# PIC32MZ1064DAG176 device description
Architecture: MIPS; Family: PIC32MZDA; Series: PIC32MZ
Registers are 32-bit, read-write, no defined reset value unless marked. A register's access mark holds for its fields unless they carry their own. Offsets are from the block's base; [hi:lo] are bit positions; {n}, {i} and the like mark numbered series; 'fields as' and 'values as' point back to an identical list.

## SDHC
Instances: SDHC 0x1f8ec004 in periph_indep
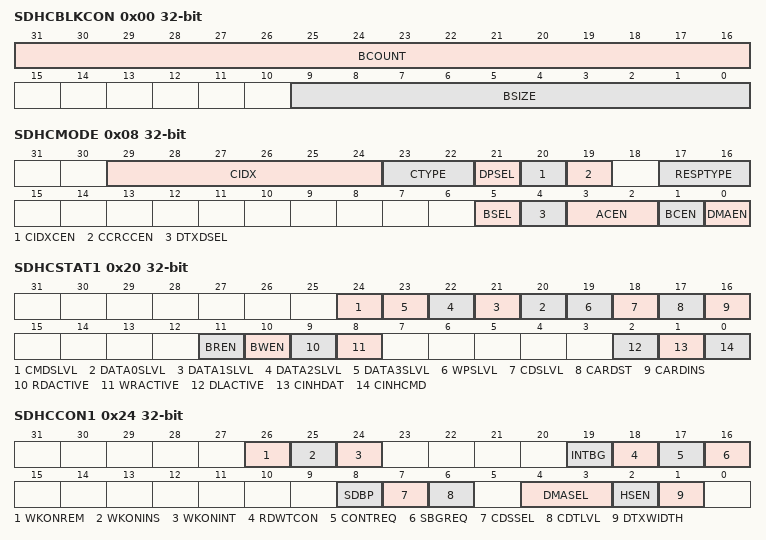
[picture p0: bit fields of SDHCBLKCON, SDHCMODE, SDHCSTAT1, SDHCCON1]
0x00 SDHCBLKCON — SDHC Block Control Register
  [31:16] BCOUNT — Blocks Count for Current Transfer bits
    0=65,535 blocks; 0=2 blocks; 0=1 block; 0=Stop count Blocks Count for Current Transfer bits
  [9:0] BSIZE — Transfer Block Size bits
    0x200=512 bytes; 0x1ff=511 bytes; 2=2 bytes; 1=1 byte; 0=No data transfer
0x04 SDHCARG — SDHC Argument Register
  [31:0] ARG
0x08 SDHCMODE
  [29:24] CIDX
  [23:22] CTYPE — Command Type bits
    3=Abort; 2=Resume; 1=Suspend; 0=Normal
  [21] DPSEL — Data Present Select bit
    1=Data is present; 0=Data is not present
  [20] CIDXCEN — Command Index Check Enable bit
    1=Command index check is enabled; 0=Command index check is disabled
  [19] CCRCCEN — Command CRC Check Enable bit
    1=Command CRC check is enabled; 0=Command CRC check is disabled
  [17:16] RESPTYPE — Response Type Select bits
    3=Response length 48; check busy after response; 2=Response length 48; 1=Response length 136; 0=No response
  [5] BSEL — Multiple/Single Block Select bit
    1=Multiple block, set when issuing multiple transfer commands using DAT lines; 0=Single block
  [4] DTXDSEL — Data Transfer Direction Select bit
    1=Read (card to SDHC); 0=Write (SDHC to card)
  [3:2] ACEN — Auto CMD12 Enable bits
    1=Auto CMD12 is enabled; 0=Auto CMD 12 is disabled
  [1] BCEN — Block Count Enable Bit
    1=Block count is enabled; 0=Block count is disabled
  [0] DMAEN — DMA Enable bit
    1=DMA (ADMA) is used to transfer data; 0=CPU is used to transfer data
{0xC+4i} SDHCRESP{i} ro (i=0..3) — SDHC Response Register
  [31:0] RESP
0x1C SDHCDATA
  [31:0] DATA
0x20 SDHCSTAT1 ro — SDHC Status Register 1
  [24] CMDSLVL — Command Line Signal Level bit
    1=CMD line is high; 0=CMD line is low
  [n+20] DATA{n}SLVL (n=0..3) — DATA{n} Signal Level bit
    1=DAT{n} line is high; 0=DAT{n} line is low
  [19] WPSLVL — Write-protect Signal Level bit
    1=Write-protect is disabled; 0=Write-protect is enabled
  [18] CDSLVL — Card Detect Signal Level bit
    1=Card is present; 0=Card is not present
  [17] CARDST — Card State Stable bit
    1=No card or inserted; 0=Reset or debouncing
  [16] CARDINS — Card Inserted bit
    1=Card inserted; 0=Reset or debouncing or no card
  [11] BREN — Buffer Read Enable bit
    1=Buffer read is enabled; 0=Buffer read is disabled
  [10] BWEN — Buffer Write Enable bit
    1=Buffer write is enabled; 0=Buffer write is disabled
  [9] RDACTIVE — Read Transfer Active bit
    1=Data is being transferred; 0=No valid data
  [8] WRACTIVE — Write Transfer Active bit
    1=Data is being transferred; 0=No valid data
  [2] DLACTIVE — DAT Line Active bit
    1=DAT line is active; 0=DAT line is inactive
  [1] CINHDAT — Command Inhibit bit (DAT) bit
    1=A command that uses the DAT line cannot be issued; 0=A command that uses the DAT line can be issued
  [0] CINHCMD — Command Inhibit bit (CMD) bit
    1=A command cannot be issued; 0=A command can only be issued using the CMD line
0x24 SDHCCON1 — SDHC Control Register 1
  [26] WKONREM — Wake-up Event Enable on SD Card Removal bit
    1=Wake-up event is enabled; 0=Wake-up event is disabled
  [25] WKONINS — Wake-up Event Enable on SD Card Insertion bit
    1=Wake-up event is enabled; 0=Wake-up event is disabled
  [24] WKONINT — Wake-up Event Enable on SD Card Interrupt bit
    1=Wake-up event is enabled; 0=Wake-up event is disabled
  [19] INTBG — Interrupt at Block Gap bit
    1=Interrupt is enabled; 0=Interrupt is disabled
  [18] RDWTCON — Read Wait Control bit
    1=Read wait control is enabled; 0=Read wait control is disabled
  [17] CONTREQ — Continue Request bit
    1=Restart; 0=No effect
  [16] SBGREQ — Stop at Block Gap Request bit
    1=Stop; 0=Transfer
  [8] SDBP — SD Bus Power bit
    1=Bus power is on; 0=Bus power is off
  [7] CDSSEL — Card Detect Signal Selection bit
    1=The card detect test level is select (for test purposes); 0=SDCDx is selected (for normal use)
  [6] CDTLVL — Card Detect Test Level bit
    1=Card is inserted; 0=Card is not inserted
  [4:3] DMASEL — DMA Select bits
    2=32-bit address ADMA2 is selected
  [2] HSEN — High-Speed Enable bit
    1=High-Speed mode is enabled; 0=Normal Speed mode is enabled
  [1] DTXWIDTH — Data Transfer Width bit
    1=4-bit mode; 0=1-bit mode
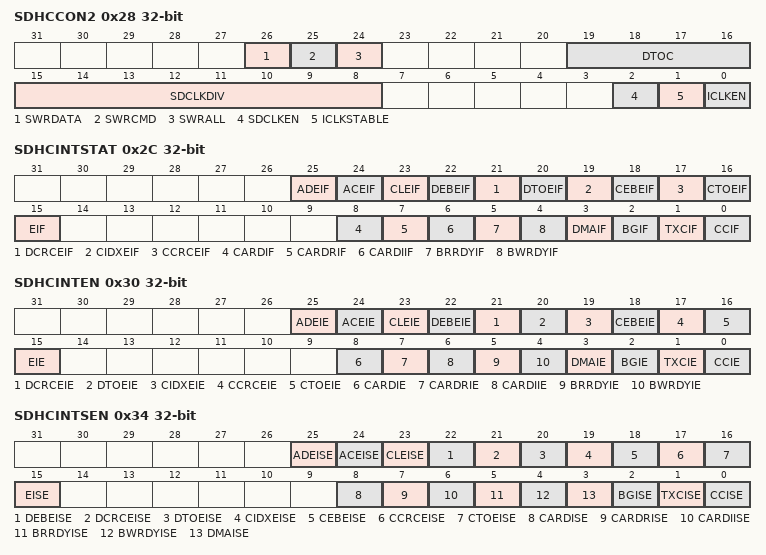
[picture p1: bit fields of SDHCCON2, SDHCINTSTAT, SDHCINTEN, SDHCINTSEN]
0x28 SDHCCON2 — SDHC Control Register 2
  [26] SWRDATA — Software Reset for DATA Line bit
    1=DMA and part of the data logic are reset; 0=Continue operation
  [25] SWRCMD — Software Reset for CMD Line bit
    1=Clears Present State and Interrupt Status registers and CMD bits; 0=Continue operation
  [24] SWRALL — Software Reset for All bit
    1=Issue reset command and reinitialize the SD card; 0=Divided Clock mode is selected
  [19:16] DTOC — Data Time-out Counter Value bits
    14=Time-out clock x 227; 1=Time-out clock x 214; 0=Time-out clock x 213
  [15:8] SDCLKDIV
  [2] SDCLKEN — SD Clock Enable bit
    1=SD clock is enabled; 0=SD clock is disabled
  [1] ICLKSTABLE — Internal Clock Stable bit
    1=Internal clock is ready; 0=Internal clock is not ready
  [0] ICLKEN — Internal Clock Enable bit
    1=Oscillate; 0=Stop
0x2C SDHCINTSTAT ro — SDHC Interrupt Status Register
  [25] ADEIF — ADMA Error Interrupt Flag bit
    1=ADMA error has occurred; 0=ADMA error has not occurred
  [24] ACEIF — Auto CMD12 Error Interrupt Flag bit
    1=Auto CMD12 error has occurred; 0=Auto CMD12 error has not occurred
  [23] CLEIF — Current-Limit Error Interrupt Flag bit
    1=Current-limit error has occurred; 0=Current-limit error has not occurred
  [22] DEBEIF — Data End Bit Error Interrupt Flag bit
    1=Data End bit error has occurred; 0=Data End bit error has not occurred
  [21] DCRCEIF — Data CRC Error Interrupt Flag bit
    1=Data CRC error has occurred; 0=Data CRC error has not occurred
  [20] DTOEIF — Data Time-out Error Interrupt Flag bit
    1=Data time-out error has occurred; 0=Data time-out error has not occurred
  [19] CIDXEIF — Command Index Error Interrupt Flag bit
    1=Command index error has occurred; 0=Command index error has not occurred
  [18] CEBEIF — Command End Bit Error Interrupt Flag bit
    1=End bit error was generated; 0=End bit error was not generated
  [17] CCRCEIF — Command CRC Error Interrupt Flag bit
    1=Command CRC error has occurred; 0=Command CRC error has not occurred
  [16] CTOEIF — Command Time-out Error Interrupt Flag bit
    1=Command time-out error has occurred; 0=Command time-out error has not occurred
  [15] EIF — Error Interrupt Flag bit
    1=Error was detected; 0=No error was detected
  [8] CARDIF — Card Interrupt Status bit
    1=Generate card interrupt; 0=Do not generate card interrupt
  [7] CARDRIF — Card Removal Interrupt Flag bit
    1=Card has been removed; 0=Card state is stable or debouncing
  [6] CARDIIF — Card Insertion Interrupt Flag bit
    1=Card has been inserted; 0=Card state is stable or debouncing
  [5] BRRDYIF — Buffer Read Ready Interrupt Flag bit
    1=Ready to read buffer; 0=Not ready to read buffer
  [4] BWRDYIF — Buffer Write Ready Interrupt Flag bit
    1=Ready to write buffer; 0=Not ready to write buffer
  [3] DMAIF — DMA Interrupt Status bit
    1=DMA interrupt was generated; 0=DMA interrupt was not generated
  [2] BGIF — Block Gap Interrupt Flag bit
    1=Transaction stopped at block gap; 0=No block gap event has occurred
  [1] TXCIF
  [0] CCIF
0x30 SDHCINTEN — SDHC Interrupt Flag Enable Register
  [25] ADEIE
  [24] ACEIE
  [23] CLEIE
  [22] DEBEIE
  [21] DCRCEIE
  [20] DTOEIE
  [19] CIDXEIE
  [18] CEBEIE
  [17] CCRCEIE
  [16] CTOEIE
  [15] EIE
  [8] CARDIE — Card Interrupt Flag Enable bit
    1=Card interrupt flag is enabled; 0=Card interrupt flag is masked
  [7] CARDRIE — Card Removal Interrupt Flag Enable bit
    1=Card removal interrupt flag is enabled; 0=Card removal interrupt flag is masked
  [6] CARDIIE — Card Insertion Interrupt Flag Enable bit
    1=Card insertion interrupt flag is enabled; 0=Card insertion interrupt flag is masked
  [5] BRRDYIE — Buffer Read Ready Interrupt Flag Enable bit
    1=Buffer read ready interrupt flag is enabled; 0=Buffer read ready interrupt flag is masked
  [4] BWRDYIE — Buffer Write Ready Interrupt Flag Enable bit
    1=Buffer write ready interrupt flag is enabled; 0=Buffer write ready interrupt flag is masked
  [3] DMAIE — DMA Interrupt Flag Enable bit
    1=DMA interrupt flag is enabled; 0=DMA interrupt flag is masked
  [2] BGIE — Block Gap Interrupt Flag Enable bit
    1=Block gap event interrupt flag is enabled; 0=Block gap event interrupt flag is masked
  [1] TXCIE
  [0] CCIE
0x34 SDHCINTSEN — SDHC Interrupt Signal Enable Register
  [25] ADEISE — ADMA Error Interrupt Signal Enable bit
    1=ADMA error signal is enabled; 0=ADMA error signal is masked
  [24] ACEISE — Auto CMD12 Error Interrupt Signal Enable bit
    1=Auto CMD12 error signal is enabled; 0=Auto CMD12 error signal is masked
  [23] CLEISE — Current-Limit Error Interrupt Signal Enable bit
    1=Current-limit error signal is enabled; 0=Current-limit error signal is masked
  [22] DEBEISE — Data End Bit Error Interrupt Signal Enable bit
    1=Data end bit error signal is enabled; 0=Data end bit error signal is masked
  [21] DCRCEISE — Data CRC Error Interrupt Signal Enable bit
    1=Data CRC error signal is enabled; 0=Data CRC error signal is masked
  [20] DTOEISE — Data Time-out Error Interrupt Signal Enable bit
    1=Data time-out error signal is enabled; 0=Data time-out error signal is masked
  [19] CIDXEISE — Command Index Error Interrupt Signal Enable bit
    1=Command index error signal is enabled; 0=Command index error signal is masked
  [18] CEBEISE — Command End Bit Error Interrupt Signal Enable bit
    1=Command End bit error signal is enabled; 0=Command End bit error signal is masked
  [17] CCRCEISE — Command CRC Error Interrupt Signal Enable bit
    1=Command CRC error signal is enabled; 0=Command CRC error signal is masked
  [16] CTOEISE — Command Time-out Error Interrupt Signal Enable bit
    1=Command time-out error signal is enabled; 0=Command time-out error signal is masked
  [15] EISE
  [8] CARDISE — Card Interrupt Signal Enable bit
    1=Card interrupt signal is enabled; 0=Card interrupt signal is masked
  [7] CARDRISE — Card Removal Interrupt Signal Enable bit
    1=Card removal signal is enabled; 0=Card removal signal is masked
  [6] CARDIISE — Card Insertion Interrupt Signal Enable bit
    1=Card insertion signal is enabled; 0=Card insertion signal is masked
  [5] BRRDYISE — Buffer Read Ready Interrupt Signal Enable bit
    1=Buffer read ready signal is enabled; 0=Buffer read ready signal is masked
  [4] BWRDYISE — Buffer Write Ready Interrupt Signal Enable bit
    1=Buffer write ready signal is enabled; 0=Buffer write ready signal is masked
  [3] DMAISE — DMA Interrupt Signal Enable bit
    1=DMA interrupt signal is enabled; 0=DMA interrupt signal is masked
  [2] BGISE — Block Gap Interrupt Signal Enable bit
    1=Block gap event signal is enabled; 0=Block gap event signal is masked
  [1] TXCISE
  [0] CCISE
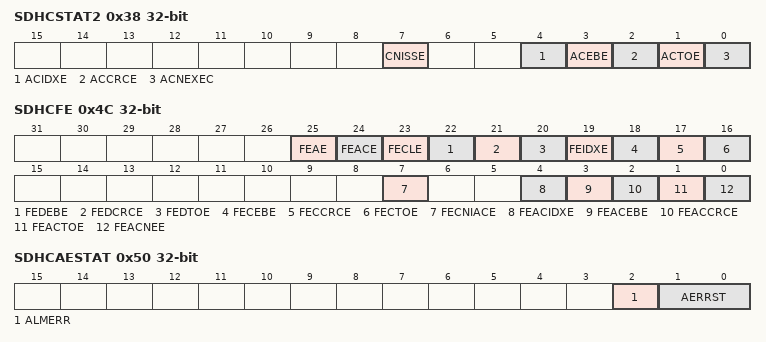
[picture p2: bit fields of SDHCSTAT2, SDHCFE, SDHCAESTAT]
0x38 SDHCSTAT2 ro — SDHC Status Register 2
  [7] CNISSE — Command Not Issued by Auto CMD12 Error bit
    1=Command was not issued; 0=No error
  [4] ACIDXE — Auto CMD12 Index Error bit
    1=Index error was generated; 0=Index error was not generated
  [3] ACEBE — Auto CMD12 End Bit Error bit
    values as SDHCINTSTAT.CEBEIF
  [2] ACCRCE — Auto CMD12 CRC Error bit
    1=CRC error was generated; 0=CRC error was not generated
  [1] ACTOE — Auto CMD12 Time-out Error bit
    1=Time-out error was generated; 0=Time-out error was not generated
  [0] ACNEXEC — Auto CMD12 Not Executed bit
    1=Auto CMD12 was not executed; 0=Auto CMD12 was executed
0x3C SDHCCAP ro — SDHC Capabilities Register
  [33:32] SLOTTYPE
  [31] ASYNCINT
  [26] VOLT3V3 — 3.3V Voltage Support bit
    0=Voltage of 3.3V is supported
  [25] SRESUME — Suspend/Resume Support bit
    0=Suspend/resume is supported; 0=Suspend/resume is not supported
  [23] HISPEED — High-speed Support bit
    0=High speed is supported; 0=High speed is not supported
  [21] ADMA2 — ADMA2 Support bit
    0=ADMA2 is supported; 0=ADMA2 is not supported
  [20] BUS8BIT
  [19:18] MBLEN — Maximum Block Length bits
    0=2048; 0=1024; 0=512
  [15:8] BASECLK — Base Clock Frequency for SDCLK bits
    63=63 MHz; 62=62 MHz; 61=61 MHz; 2=2 MHz; 1=1 MHz
  [7] TOCLKU — Time-out Clock Unit bit
    1=Time-out clock unit is in kHz; 0=Time-out clock unit is in MHz
  [5:0] TOCLKFREQ — Time-out Clock Frequency bits
    0x7e0=63 kHz or 63 MHz; 0x7c0=62 kHz or 62 MHz; 0x7a0=61 kHz or 61 MHz; 64=2 kHz or 2 MHz; 32=1 kHz or 1 MHz
0x44 SDHCMAXCAP ro — SDHC Maximum Current Capabilities Register
  [7:0] MC3V3 — Maximum Current for 3.3V bits
    255=1020 mA; 254=1016 mA; 253=1012 mA; 3=12 mA; 2=8 mA; 1=4 mA
0x4C SDHCFE wo — SDHC Force Event Register
  [25] FEAE
  [24] FEACE — Force Event for Auto CMD 12 Error bit
    1=Interrupt was generated; 0=Interrupt was not generated
  [23] FECLE — Force Event for Current-Limit Error bit
    1=Interrupt was generated; 0=Interrupt was not generated
  [22] FEDEBE — Force Event for Data End Bit Error bit
    1=Interrupt was generated; 0=Interrupt was not generated
  [21] FEDCRCE — Force Event for Data CRC Error bit
    1=Interrupt was generated; 0=Interrupt was not generated
  [20] FEDTOE — Force Event for Data Time-out Error bit
    1=Interrupt was generated; 0=Interrupt was not generated
  [19] FEIDXE — Force Event for Command Index Error bit
    1=Interrupt was generated; 0=Interrupt was not generated
  [18] FECEBE — Force Event for Command End Bit Error bit
    1=Interrupt was generated; 0=Interrupt was not generated
  [17] FECCRCE — Force Event for Command CRC Error bit
    1=Interrupt was generated; 0=Interrupt was not generated
  [16] FECTOE — Force Event for Command Time-out Error bit
    1=Interrupt was generated; 0=Interrupt was not generated
  [7] FECNIACE — Force Event for Command Not Issued by Auto CMD12 Error bit
    1=Interrupt was generated; 0=Interrupt was not generated
  [4] FEACIDXE — Force Event for Auto CMD12 Index Error bit
    1=Interrupt was generated; 0=Interrupt was not generated
  [3] FEACEBE — Force Event for Auto CMD12 End Bit Error bit
    1=Interrupt was generated; 0=Interrupt was not generated
  [2] FEACCRCE
  [1] FEACTOE — Force Event for Auto CMD12 Time-out Error bit
    1=Interrupt was generated; 0=Interrupt was not generated
  [0] FEACNEE — Force Event for Auto CMD12 Not Executed Error bit
    1=Interrupt was generated; 0=Interrupt was not generated
0x50 SDHCAESTAT ro
  [2] ALMERR, [1:0] AERRST
0x54 SDHCAADDR — SDHC ADMA Address Register
  [31:0] ADDR

## Notices in the file
Copyright (c) 2017 Microchip Technology Inc.
SPDX-License-Identifier: Apache-2.0
Licensed under the Apache License, Version 2.0 (the "License");
you may not use this file except in compliance with the License.
You may obtain a copy of the License at
http://www.apache.org/licenses/LICENSE-2.0
Unless required by applicable law or agreed to in writing, software
distributed under the License is distributed on an "AS IS" BASIS,
WITHOUT WARRANTIES OR CONDITIONS OF ANY KIND, either express or implied.
See the License for the specific language governing permissions and
limitations under the License.
